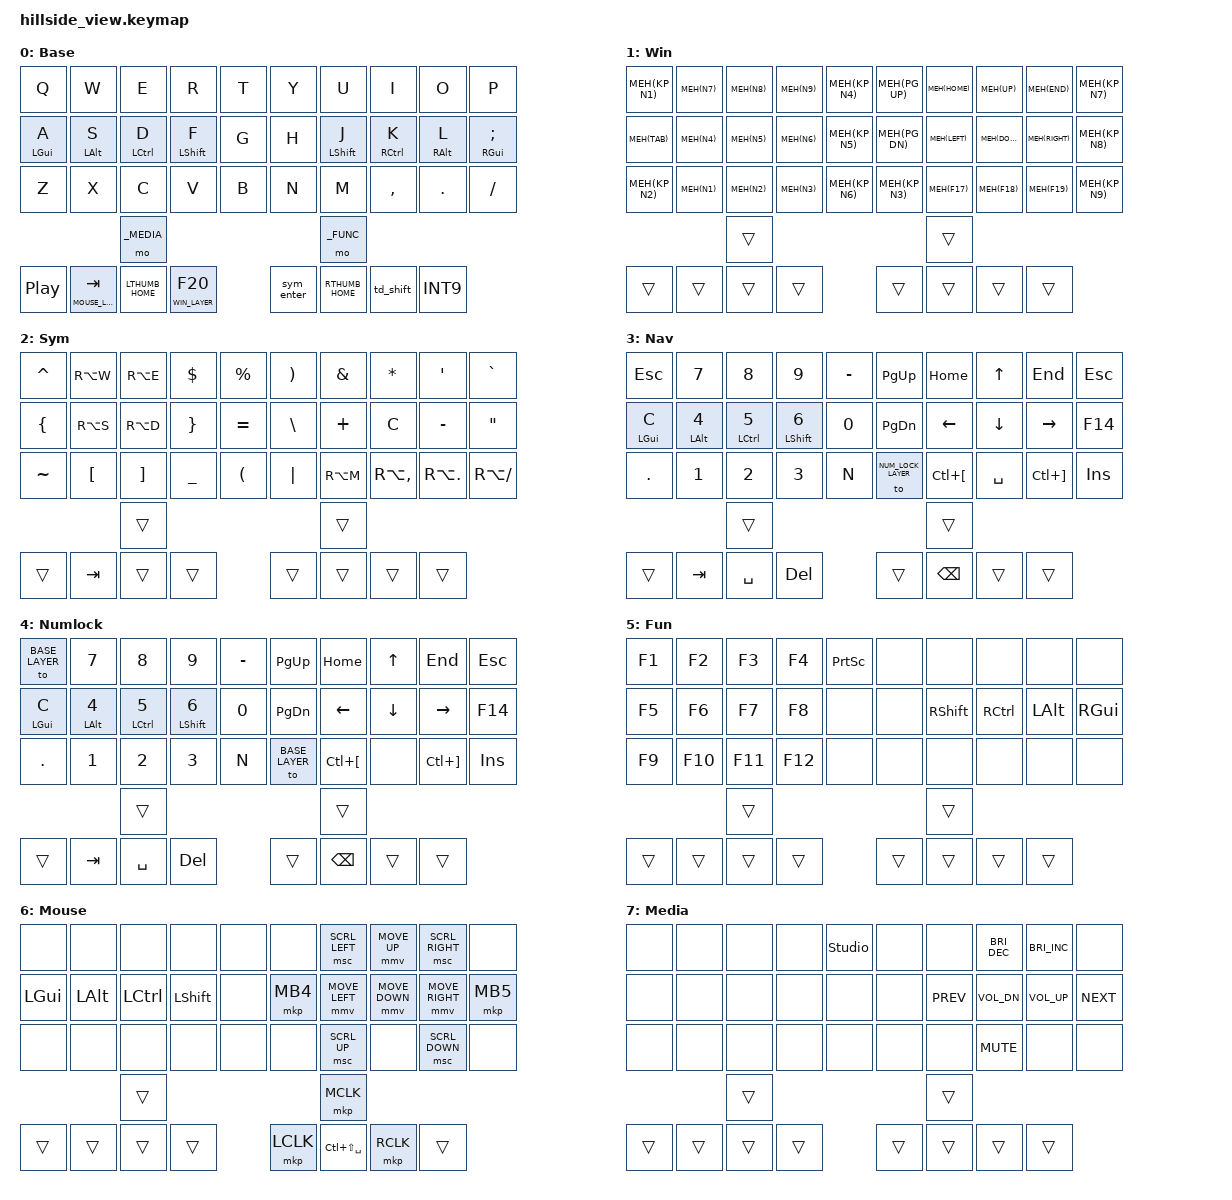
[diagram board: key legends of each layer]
#include <behaviors.dtsi>
#include <behaviors/mouse_keys.dtsi>
#include <behaviors/studio_unlock.dtsi>
#include <dt-bindings/zmk/bt.h>
#include <dt-bindings/zmk/ext_power.h>
#include <dt-bindings/zmk/keys.h>

#define ZMK_MOUSE_DEFAULT_MOVE_VAL 1500  // 600
#define ZMK_MOUSE_DEFAULT_SCRL_VAL 20    // 10

#include <dt-bindings/zmk/mouse.h>
#include <dt-bindings/zmk/outputs.h>
#include <dt-bindings/zmk/pointing.h>

#define MEH(key) LC(LA(LG(key)))
#define MEHS(key) LS(LC(LA(LG(key))))

#define _BASE 0
#define BASE_LAYER 0
#define _WIN 1
#define WIN_LAYER 1
#define SYMBOLS_LAYER 2
#define NAV_LAYER 3
#define NUM_LOCK_LAYER 4
#define _FUNC 5
#define MOUSE_LAYER 6
#define _MEDIA 7

#define EZ_SL(layer)  bsl (layer) (layer)
#define EZ_SK(mod)    bsk (mod) (mod)

#define HRM_A &hrm LGUI  A
#define HRM_S &hrm LALT  S
#define HRM_D &hrm LCTRL D
#define HRM_F &hrm LSHFT F
#define HRM_J &hrm LSHFT J
#define HRM_K &hrm RCTRL K
#define HRM_L &hrm RALT  L
#define HRM_SEMI &hrm RGUI SEMI

#define LTHUMB_HRM &lt NAV_LAYER SPACE
#define RTHUMB_HRM &bspc_del

#define LTHUMB_TUCK   &lt MOUSE_LAYER TAB
#define LTHUMB_HOME   LTHUMB_HRM
#define LTHUMB_REACH  &sc WIN_LAYER F20
#define RTHUMB_REACH  &sym_enter
#define RTHUMB_HOME   RTHUMB_HRM
#define RTHUMB_TUCK   &td_shift

#define X_PREV  &kp LC(LBKT)
#define X_NEXT  &kp LC(RBKT)

// first row
#define S_CARET &kp CARET
#define S_LT    &kp RA(W)
#define S_GT    &kp RA(E)
#define S_DLLR  &kp DLLR
#define S_PRCNT &kp PRCNT
#define S_AT    &kp RPAR
#define S_AMPS  &kp AMPS
#define S_STAR  &kp STAR
#define S_SQT   &kp SQT
#define S_GRAVE &kp GRAVE

// second row
#define S_LBRC  &kp LBRC
#define S_LPAR  &kp RA(S)
#define S_RPAR  &kp RA(D)
#define S_RBRC  &kp RBRC
#define S_EQUAL &kp EQUAL
#define S_BSLH  &kp BSLH
#define S_PLUS  &kp PLUS
#define S_MINUS &kp C
#define S_FSLH  &kp MINUS
#define S_DQT   &kp DQT

// third row
#define S_TILDE &kp TILDE
#define S_LBKT  &kp LBKT
#define S_RBKT  &kp RBKT
#define S_UNDER &kp UNDER
#define S_HASH  &kp LPAR
#define S_PIPE  &kp PIPE
#define S_EXCL  &kp RA(M)
#define S_SEMI  &kp RA(COMMA)
#define S_COLON &kp RA(DOT)
#define S_QMARK &kp RA(FSLH)

// extra
#define S_COMMA &kp DOT
#define S_DOT   &kp N

#define SHORT_TAPPING_TERM 150
#define QUICK_TAP 200
#define QUICK_TAP_MS QUICK_TAP
#define TAPPING_TERM 300
#define TAPPING_TERM_MS TAPPING_TERM

&mmv {
    acceleration-exponent = <1>;      // 1
    time-to-max-speed-ms = <500>;     // 300
    delay-ms = <0>;                   // 0
};

&msc {
    acceleration-exponent = <1>;      // 0
    time-to-max-speed-ms = <40>;      // 300
    delay-ms = <0>;                   // 0
};

&sl { ignore-modifiers; }; // keep one-shot-mods when chained into a one-shot-layer
&sk { quick-release; };    // must-have! (lots of false positives otherwise)

/ {
    behaviors {
        caps_word_ergol: caps_word_ergol {
            compatible = "zmk,behavior-caps-word-ergol";
            #binding-cells = <0>;
            // DOT = ',' in Ergo-L, C = '-' in Ergo-L: continue but don't shift
            // UNDERSCORE: from Sym layer, should not break caps_word
            continue-list = <BACKSPACE DELETE DOT C UNDERSCORE>;
        };

        hrm: homerow_mods {
            compatible = "zmk,behavior-hold-tap";
            #binding-cells = <2>;
            tapping-term-ms = <TAPPING_TERM_MS>;
            quick-tap-ms = <QUICK_TAP_MS>;
            flavor = "tap-preferred";
            bindings = <&kp>, <&kp>;
        };

        sc: space_cadet { // same as lt, but with hold-preferred
            compatible = "zmk,behavior-hold-tap";
            #binding-cells = <2>;
            tapping-term-ms = <SHORT_TAPPING_TERM>;
            quick-tap-ms = <QUICK_TAP>;
            flavor = "hold-preferred";
            bindings = <&mo>, <&kp>;
        };

        // Backspace thumb: hold = NAV in both cases; tap = Backspace, Shift+tap = Delete.
        // A hold-tap must keep #binding-cells=2, so instead of nesting a morph inside it we
        // put the morph on top and switch between two full space-cadet behaviors.
        // Shift is consumed, so DEL is sent unshifted.
        bspc_del: bspc_del {
            compatible = "zmk,behavior-mod-morph";
            #binding-cells = <0>;
            bindings = <&sc NAV_LAYER BACKSPACE>, <&sc NAV_LAYER DELETE>;
            mods = <(MOD_LSFT|MOD_RSFT)>;
        };

        // Sym/Enter thumb: tap=Enter, hold=Sym, Shift+tap=Shift+Enter, Shift+hold=Shift+RAlt
        // Outer morph: Ctrl/Gui/LAlt bypass to normal Sym (no AltGr morph)
        sym_enter: sym_enter {
            compatible = "zmk,behavior-mod-morph";
            #binding-cells = <0>;
            bindings = <&sym_enter_inner>, <&sc SYMBOLS_LAYER ENTER>;
            mods      = <(MOD_LCTL|MOD_RCTL|MOD_LGUI|MOD_RGUI|MOD_LALT)>;
            keep-mods = <(MOD_LCTL|MOD_RCTL|MOD_LGUI|MOD_RGUI|MOD_LALT)>;
        };
        // Inner morph: Shift -> RAlt hold-tap, otherwise normal Sym
        sym_enter_inner: sym_enter_inner {
            compatible = "zmk,behavior-mod-morph";
            #binding-cells = <0>;
            bindings = <&sc SYMBOLS_LAYER ENTER>, <&kpht RALT ENTER>;
            mods      = <(MOD_LSFT|MOD_RSFT)>;
            keep-mods = <(MOD_LSFT|MOD_RSFT)>;
        };
        kpht: kp_hold_tap {
            compatible = "zmk,behavior-hold-tap";
            #binding-cells = <2>;
            tapping-term-ms = <SHORT_TAPPING_TERM>;
            quick-tap-ms = <QUICK_TAP>;
            flavor = "hold-preferred";
            bindings = <&kp>, <&kp>;
        };

    // like ZMK's sticky layer (sl) but with a more robust timing
        osl: one_shot_layer {
            compatible = "zmk,behavior-macro-one-param";
            #binding-cells = <1>;
            tap-ms = <0>;
            wait-ms = <0>;
            bindings = <&macro_param_1to1>, <&macro_tap &sl MACRO_PLACEHOLDER>;
        };
        osm: one_shot_modifier {
            compatible = "zmk,behavior-macro-one-param";
            #binding-cells = <1>;
            tap-ms = <0>;
            wait-ms = <0>;
            bindings = <&macro_param_1to1>, <&macro_tap &sk MACRO_PLACEHOLDER>;
        };
        bsl: better_sticky_layer {
            compatible = "zmk,behavior-hold-tap";
            #binding-cells = <2>;
            tapping-term-ms = <TAPPING_TERM>;
            flavor = "tap-preferred";
            bindings = <&mo>, <&osl>;
        };
        td_shift: tap_dance_shift {
            compatible = "zmk,behavior-tap-dance";
            #binding-cells = <0>;
            tapping-term-ms = <230>;
            bindings = <&sk LSHIFT>, <&caps_word_ergol>;
        };

        bsk: better_sticky_key {
            compatible = "zmk,behavior-hold-tap";
            #binding-cells = <2>;
            tapping-term-ms = <TAPPING_TERM>;
            flavor = "tap-preferred";
            bindings = <&kp>, <&osm>;
        };
    };

    combos {
        compatible = "zmk,combos";

        combo_fn {
            timeout-ms = <50>;
            key-positions = <35 36>;
            bindings = <&mo _FUNC>;
            layers = <_BASE>;
        };
    };

    keymap {
        compatible = "zmk,keymap";

        base_layer {                            // 0 = _BASE
            display-name = "Base";
            bindings = <
&kp Q          &kp W         &kp E            &kp R          &kp T             &kp Y     &kp U         &kp I              &kp O         &kp P
HRM_A          HRM_S         HRM_D            HRM_F          &kp G             &kp H     HRM_J         HRM_K              HRM_L         HRM_SEMI
&kp Z          &kp X         &kp C            &kp V          &kp B             &kp N     &kp M         &kp COMMA          &kp DOT       &kp FSLH
                                     &mo _MEDIA                                               &mo _FUNC
&kp C_PP         LTHUMB_TUCK        LTHUMB_HOME  LTHUMB_REACH             RTHUMB_REACH  RTHUMB_HOME    RTHUMB_TUCK    &kp INT9
            >;
        };

        win_layer {                             // 1 = _WIN
            display-name = "Win";
            bindings = <
&kp MEH(KP_N1) &kp MEH(N7)        &kp MEH(N8)        &kp MEH(N9)       &kp MEH(KP_N4)      &kp MEH(PG_UP)   &kp MEH(HOME)      &kp MEH(UP)        &kp MEH(END)        &kp MEH(KP_N7)
&kp MEH(TAB)   &kp MEH(N4)        &kp MEH(N5)        &kp MEH(N6)       &kp MEH(KP_N5)      &kp MEH(PG_DN)   &kp MEH(LEFT)      &kp MEH(DOWN)      &kp MEH(RIGHT)      &kp MEH(KP_N8)
&kp MEH(KP_N2) &kp MEH(N1)        &kp MEH(N2)        &kp MEH(N3)       &kp MEH(KP_N6)      &kp MEH(KP_N3)   &kp MEH(F17)       &kp MEH(F18)       &kp MEH(F19)        &kp MEH(KP_N9)
                  &trans                                    &trans
         &trans   &trans   &trans   &trans         &trans  &trans  &trans   &trans
            >;
        };

        sym_layer {                             // 2 = SYMBOLS_LAYER
            display-name = "Sym";
            bindings = <
S_CARET S_LT    S_GT    S_DLLR  S_PRCNT      S_AT    S_AMPS  S_STAR  S_SQT   S_GRAVE
S_LBRC  S_LPAR  S_RPAR  S_RBRC  S_EQUAL      S_BSLH  S_PLUS  S_MINUS S_FSLH  S_DQT
S_TILDE S_LBKT  S_RBKT  S_UNDER S_HASH       S_PIPE  S_EXCL  S_SEMI  S_COLON S_QMARK
                  &trans                                       &trans
         &trans   &kp TAB    &trans   &trans          &trans   &trans   &trans   &trans
            >;
        };

        nav_layer {                             // 3 = NAV_LAYER
            display-name = "Nav";
            bindings = <
&kp ESC             &kp N7         &kp N8           &kp N9          S_FSLH             &kp PG_UP                &kp HOME     &kp UP       &kp END     &kp ESC
&hrm LGUI C     &hrm LALT N4       &hrm LCTRL N5    &hrm LSHFT N6    &kp N0            &kp PG_DN                &kp LEFT     &kp DOWN     &kp RIGHT   &kp F14
S_COMMA             &kp N1         &kp N2           &kp N3          S_DOT              &to NUM_LOCK_LAYER       X_PREV       &kp SPACE    X_NEXT      &kp INS
                  &trans                                          &trans
         &trans   &kp TAB   &kp SPACE   &kp DEL       &trans   &kp BSPC   &trans   &trans
            >;
        };

        num_lock_layer {                        // 4 = NUM_LOCK_LAYER
            display-name = "Numlock";
            bindings = <
&to BASE_LAYER  &kp N7             &kp N8           &kp N9              S_FSLH             &kp PG_UP               &kp HOME     &kp UP    &kp END     &kp ESC
&hrm LGUI C     &hrm LALT N4       &hrm LCTRL N5    &hrm LSHFT N6       &kp N0             &kp PG_DN               &kp LEFT     &kp DOWN  &kp RIGHT   &kp F14
S_COMMA                 &kp N1         &kp N2           &kp N3          S_DOT              &to BASE_LAYER          X_PREV       &none     X_NEXT      &kp INS
                  &trans                                 &trans
         &trans   &kp TAB   &kp SPACE   &kp DEL       &trans   &kp BSPC   &trans   &trans
            >;
        };

        func_layer {                            // 5 = _FUNC
            display-name = "Fun";
            bindings = <
&kp F1    &kp F2    &kp F3    &kp F4    &kp PSCRN       &none    &none        &none        &none      &none
&kp F5    &kp F6    &kp F7    &kp F8    &none           &none    &kp RSHFT    &kp RCTRL    &kp LALT   &kp RGUI
&kp F9    &kp F10   &kp F11   &kp F12   &none           &none    &none        &none        &none      &none
                  &trans                               &trans
         &trans   &trans   &trans   &trans    &trans   &trans   &trans   &trans
            >;
        };

        mouse_layer {                           // 6 = MOUSE_LAYER
            display-name = "Mouse";
            bindings = <
&none          &none         &none            &none          &none           &none      &msc SCRL_LEFT  &mmv MOVE_UP     &msc SCRL_RIGHT    &none
&kp LGUI       &kp LALT      &kp LCTRL        &kp LSHFT      &none           &mkp MB4   &mmv MOVE_LEFT  &mmv MOVE_DOWN   &mmv MOVE_RIGHT   &mkp MB5
&none          &none         &none            &none          &none           &none      &msc SCRL_UP    &none            &msc SCRL_DOWN     &none
                  &trans                                  &mkp MCLK
         &trans   &trans   &trans   &trans    &mkp LCLK   &kp LC(LS(SPACE))   &mkp RCLK   &trans
            >;
        };

        media_layer {                           // 7 = _MEDIA
            display-name = "Media";
            bindings = <
&none  &none  &none    &none  &studio_unlock           &none   &none        &kp C_BRI_DEC    &kp C_BRI_INC   &none
&none  &none  &none    &none  &none                    &none   &kp K_PREV   &kp C_VOL_DN     &kp C_VOL_UP   &kp K_NEXT
&none  &none  &none    &none  &none                    &none   &none        &kp K_MUTE       &none          &none
                  &trans                                    &trans
         &trans   &trans   &trans   &trans         &trans   &trans   &trans   &trans
            >;
        };
    };
};
